AUTOSAR XML (schema 00046)
package /ComponentTypes
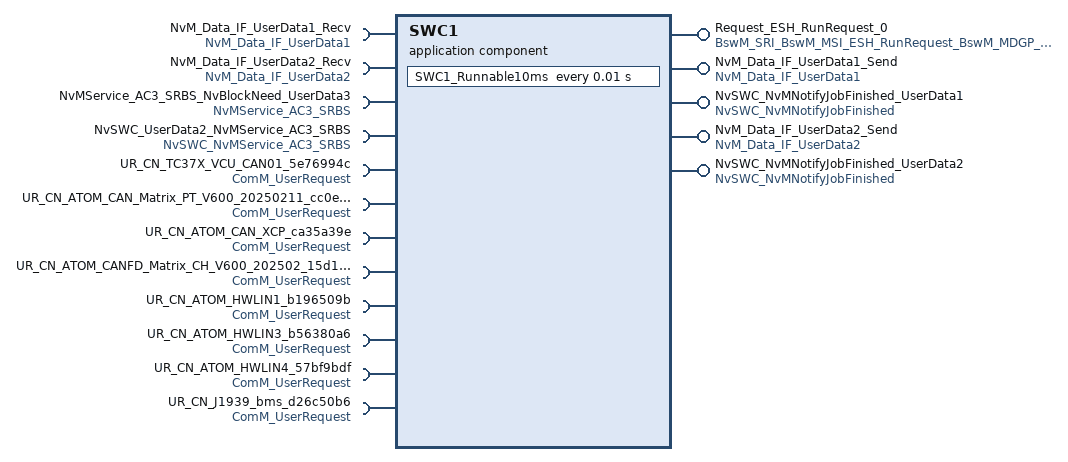
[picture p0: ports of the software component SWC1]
  application sw component type SWC1
    provide port Request_ESH_RunRequest_0: nonqueued-sender-com-spec=requestedMode, provided-interface=BswM_SRI_BswM_MSI_ESH_RunRequest_BswM_MDGP_ESH_RunRequest
    provide port NvM_Data_IF_UserData1_Send: nv-provide-com-spec{ram-block-init-value=10 x 0, rom-block-init-value=10 x 0, variable=Element_UserData1}, provided-interface=NvM_Data_IF_UserData1
    require port NvM_Data_IF_UserData1_Recv: nv-require-com-spec{init-value=10 x 0, variable=Element_UserData1}, required-interface=NvM_Data_IF_UserData1
    provide port NvSWC_NvMNotifyJobFinished_UserData1: server-com-spec{operation=JobFinished, queue-length=1}, provided-interface=NvSWC_NvMNotifyJobFinished
    provide port NvM_Data_IF_UserData2_Send: nv-provide-com-spec=Element_UserData2, provided-interface=NvM_Data_IF_UserData2
    require port NvM_Data_IF_UserData2_Recv: nv-require-com-spec=Element_UserData2, required-interface=NvM_Data_IF_UserData2
    provide port NvSWC_NvMNotifyJobFinished_UserData2: server-com-spec{operation=JobFinished, queue-length=1}, provided-interface=NvSWC_NvMNotifyJobFinished
    10 x require port:
      NvMService_AC3_SRBS_NvBlockNeed_UserData3: required-com-specs=[WriteBlock, SetRamBlockStatus, ReadBlock, InvalidateNvBlock, GetErrorStatus, EraseBlock], required-interface=NvMService_AC3_SRBS
      NvSWC_UserData2_NvMService_AC3_SRBS: required-com-specs=[WriteBlock, SetRamBlockStatus, ReadBlock, InvalidateNvBlock, GetErrorStatus, EraseBlock], required-interface=NvSWC_NvMService_AC3_SRBS
      UR_CN_TC37X_VCU_CAN01_5e76994c: required-com-specs=[RequestComMode, GetCurrentComMode, GetMaxComMode, GetRequestedComMode], required-interface=ComM_UserRequest
      UR_CN_ATOM_CAN_Matrix_PT_V600_20250211_cc0efb79: required-com-specs=[RequestComMode, GetCurrentComMode, GetMaxComMode, GetRequestedComMode], required-interface=ComM_UserRequest
      UR_CN_ATOM_CAN_XCP_ca35a39e: required-com-specs=[RequestComMode, GetCurrentComMode, GetMaxComMode, GetRequestedComMode], required-interface=ComM_UserRequest
      UR_CN_ATOM_CANFD_Matrix_CH_V600_202502_15d11ab0: required-com-specs=[RequestComMode, GetCurrentComMode, GetMaxComMode, GetRequestedComMode], required-interface=ComM_UserRequest
      UR_CN_ATOM_HWLIN1_b196509b: required-com-specs=[RequestComMode, GetCurrentComMode, GetMaxComMode, GetRequestedComMode], required-interface=ComM_UserRequest
      UR_CN_ATOM_HWLIN3_b56380a6: required-com-specs=[RequestComMode, GetCurrentComMode, GetMaxComMode, GetRequestedComMode], required-interface=ComM_UserRequest
      UR_CN_ATOM_HWLIN4_57bf9bdf: required-com-specs=[RequestComMode, GetCurrentComMode, GetMaxComMode, GetRequestedComMode], required-interface=ComM_UserRequest
      UR_CN_J1939_bms_d26c50b6: required-com-specs=[RequestComMode, GetCurrentComMode, GetMaxComMode, GetRequestedComMode], required-interface=ComM_UserRequest
    behavior SWC1_InternalBehavior
      ar-typed-per-instance-memorys:
        data NvBlockNeed_UserData3_MirrorBlock: sw-calibration-access=READ-ONLY, type=NvM_Array10Bytes
      init event SWC1_InitEvent: start-on-event=SWC1_Init
      timing event TMT_SWC1_Runnable10ms: start-on-event=SWC1_Runnable10ms, period=0.01
      operation invoked event OIT_NvSWC_NvMNotifyJobFinished_UserData1_JobFinished_NvSWC_NvMNotifyJobFinished_UserData1_JobFinished: start-on-event=NvSWC_NvMNotifyJobFinished_UserData1_JobFinished, operation=NvSWC_NvMNotifyJobFinished_UserData1.JobFinished
      operation invoked event OIT_NvSWC_NvMNotifyJobFinished_UserData2_JobFinished_NvSWC_NvMNotifyJobFinished_UserData2_JobFinished: start-on-event=NvSWC_NvMNotifyJobFinished_UserData2_JobFinished, operation=NvSWC_NvMNotifyJobFinished_UserData2.JobFinished
      4 x runnable:
        SWC1_Init
          data-send-points:
            access SEND_Request_ESH_RunRequest_0_requestedMode: accessed-variable=Request_ESH_RunRequest_0.requestedMode
        SWC1_Runnable10ms
          data-receive-point-by-arguments:
            access REC_NvM_Data_IF_UserData1_Recv_Element_UserData1: accessed-variable=NvM_Data_IF_UserData1_Recv.Element_UserData1
            access REC_NvM_Data_IF_UserData2_Recv_Element_UserData2: accessed-variable=NvM_Data_IF_UserData2_Recv.Element_UserData2
          data-send-points:
            access SEND_NvM_Data_IF_UserData1_Send_Element_UserData1: accessed-variable=NvM_Data_IF_UserData1_Send.Element_UserData1
            access SEND_NvM_Data_IF_UserData2_Send_Element_UserData2: accessed-variable=NvM_Data_IF_UserData2_Send.Element_UserData2
          13 x sync call:
            SC_NvMService_AC3_SRBS_NvBlockNeed_UserData3_ReadBlock: operation=NvMService_AC3_SRBS_NvBlockNeed_UserData3.ReadBlock
            SC_NvMService_AC3_SRBS_NvBlockNeed_UserData3_SetRamBlockStatus: operation=NvMService_AC3_SRBS_NvBlockNeed_UserData3.SetRamBlockStatus
            SC_NvMService_AC3_SRBS_NvBlockNeed_UserData3_WriteBlock: operation=NvMService_AC3_SRBS_NvBlockNeed_UserData3.WriteBlock
            SC_NvSWC_NvMService_AC3_SRBS_SetRamBlockStatus: operation=NvSWC_UserData2_NvMService_AC3_SRBS.SetRamBlockStatus
            SC_UR_CN_TC37X_VCU_CAN01_5e76994c_GetCurrentComMode: operation=UR_CN_TC37X_VCU_CAN01_5e76994c.GetCurrentComMode
            SC_UR_CN_TC37X_VCU_CAN01_5e76994c_RequestComMode: operation=UR_CN_TC37X_VCU_CAN01_5e76994c.RequestComMode
            SC_UR_CN_ATOM_CANFD_Matrix_CH_V600_202502_15d11ab0_RequestComMode: operation=UR_CN_ATOM_CANFD_Matrix_CH_V600_202502_15d11ab0.RequestComMode
            SC_UR_CN_ATOM_CAN_Matrix_PT_V600_20250211_cc0efb79_RequestComMode: operation=UR_CN_ATOM_CAN_Matrix_PT_V600_20250211_cc0efb79.RequestComMode
            SC_UR_CN_ATOM_CAN_XCP_ca35a39e_RequestComMode: operation=UR_CN_ATOM_CAN_XCP_ca35a39e.RequestComMode
            SC_UR_CN_ATOM_HWLIN1_b196509b_RequestComMode: operation=UR_CN_ATOM_HWLIN1_b196509b.RequestComMode
            SC_UR_CN_ATOM_HWLIN3_b56380a6_RequestComMode: operation=UR_CN_ATOM_HWLIN3_b56380a6.RequestComMode
            SC_UR_CN_ATOM_HWLIN4_57bf9bdf_RequestComMode: operation=UR_CN_ATOM_HWLIN4_57bf9bdf.RequestComMode
            SC_UR_CN_J1939_bms_d26c50b6_RequestComMode: operation=UR_CN_J1939_bms_d26c50b6.RequestComMode
        NvSWC_NvMNotifyJobFinished_UserData1_JobFinished
        NvSWC_NvMNotifyJobFinished_UserData2_JobFinished
      swc service dependency NvBlockNeed_UserData3: assigned-ports=role-based-port-assignment={port-prototype=NvMService_AC3_SRBS_NvBlockNeed_UserData3, role=NvMService_AC3_SRBS}
        assigned-datas:
          role=ramBlock, used-data-element=NvBlockNeed_UserData3_MirrorBlock
          role=defaultValue, used-parameter-element=NvBlockNeed_UserData3_DefaultValue
        service-needs:
          nv block needs NvBlockNeed_UserData3: calc-ram-block-crc=false, check-static-block-id=false, n-data-sets=1, n-rom-blocks=1, ram-block-status-control=API, readonly=false, reliability=ERROR-DETECTION, resistant-to-changed-sw=true, restore-at-start=true, store-at-shutdown=true, store-cyclic=false, store-emergency=false, store-immediate=false, use-auto-validation-at-shut-down=false, use-crc-comp-mechanism=false, write-only-once=false, write-verification=false
      shared-parameters:
        parameter data prototype NvBlockNeed_UserData3_DefaultValue: sw-calibration-access=READ-WRITE, type=NvM_Array10Bytes, init-value=10 x 0
        parameter data prototype CalibrationParameter: sw-calibration-access=READ-WRITE, type=uint16, init-value=7
  swc implementation SWC1_Implementation: behavior=SWC1_InternalBehavior
